AUTOSAR XML (schema 00048)
package /AUTOLIV/SoftwareComponents/SFR
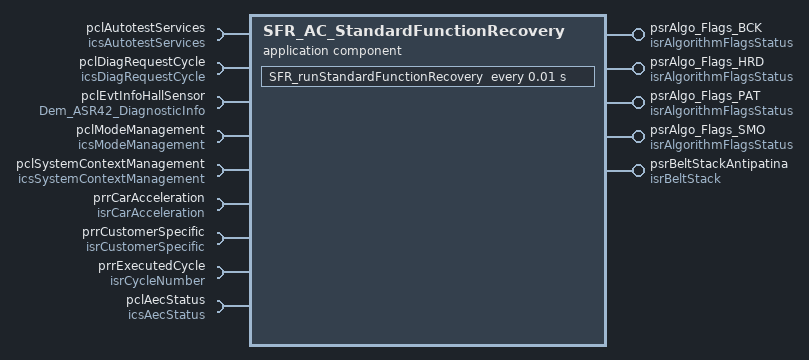
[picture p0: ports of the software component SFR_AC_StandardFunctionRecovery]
  application sw component type SFR_AC_StandardFunctionRecovery
    8 x require port:
      pclAutotestServices: required-com-specs=[GetLastCriticalAutotestID, GetTestResult], required-interface=icsAutotestServices
      pclDiagRequestCycle: required-com-specs=[ClearDiagRequestCycle, GetDiagRequestCycle], required-interface=icsDiagRequestCycle
      pclEvtInfoHallSensor: required-interface=Dem_ASR42_DiagnosticInfo
        required-com-specs:
          GetDTCOfEvent
          GetDebouncingOfEvent
          GetEventExtendedDataRecord
          GetEventExtendedDataRecordEx
          GetEventFailed
          GetEventFreezeFrameData
          GetEventFreezeFrameDataEx
          GetEventStatus
          GetEventTested
          GetFaultDetectionCounter
      pclModeManagement: client-com-spec=CheckModeStatus, required-interface=icsModeManagement
      pclSystemContextManagement: required-interface=icsSystemContextManagement
        required-com-specs:
          GetBatteryHysteresisThrs
          GetLastTensionningState
          GetMonitoredCycle
          ManageSystemContextStorage
          RestoreSystemContext
          SuperviseKL30bg
      prrCarAcceleration: nonqueued-receiver-com-spec{data-element=b8IsCarAccelerationLow, init-value=constant-reference=APPLINIT_KB8_CAR_ACCEL_LOW_TRUE}, required-interface=isrCarAcceleration
      prrCustomerSpecific: required-interface=isrCustomerSpecific
        required-com-specs:
          data-element=b8HardReleaseRequest, init-value=constant-reference=APPLINIT_KB8_BOOLEAN_FALSE
          data-element=b8IsCarCrankingActive, init-value=constant-reference=APPLINIT_KB8_CAR_CRANKING_ACTIVE_TRUE
          data-element=b8IsCarCrashDetected, init-value=constant-reference=APPLINIT_KB8_CAR_CRASH_DETECTED_FALSE
          data-element=b8IsTrigOffEventAllowed
          data-element=b8PreCrashRequestEnable, init-value=constant-reference=APPLINIT_KB8_BOOLEAN_FALSE
          data-element=u8BeltSlackStatus, init-value=constant-reference=APPLINIT_KU8_BELT_SLACK_STATUS_NOT_DEFINED
          data-element=u8HapticRequest, init-value=constant-reference=APPLINIT_KU8_HAPTIC_REQUEST_NO
          data-element=u8PreCrashRequest, init-value=constant-reference=APPLINIT_KU8_PRE_CRASH_REQUEST_NO_REQUEST
          data-element=u8TriggerRequest
          data-element=b8SignalRelInhibition
      prrExecutedCycle: nonqueued-receiver-com-spec{data-element=u8CycleNumber, init-value=constant-reference=APPLINIT_KU8_CYCLE_NUMBER_NONE}, required-interface=isrCycleNumber
    5 x provide port:
      psrAlgo_Flags_BCK: provided-interface=isrAlgorithmFlagsStatus
        provided-com-specs:
          data-element=b8InterruptFlag, uses-end-to-end-protection=true, init-value=KB8_ALGO_FLAG_OFF
          data-element=b8PreActivationFlag, uses-end-to-end-protection=true
          data-element=b8PreConditionsFlag, uses-end-to-end-protection=true
          data-element=b8TriggerFlag, uses-end-to-end-protection=true
          data-element=u8TriggeringSource, uses-end-to-end-protection=true
      psrAlgo_Flags_HRD: provided-interface=isrAlgorithmFlagsStatus
        provided-com-specs:
          data-element=b8InterruptFlag, uses-end-to-end-protection=true, init-value=constant-reference=APPLINIT_KB8_ALGO_FLAG_FALSE
          data-element=b8PreActivationFlag, uses-end-to-end-protection=true, init-value=constant-reference=APPLINIT_KB8_ALGO_FLAG_FALSE
          data-element=b8PreConditionsFlag, uses-end-to-end-protection=true, init-value=constant-reference=APPLINIT_KB8_ALGO_FLAG_FALSE
          data-element=b8TriggerFlag, uses-end-to-end-protection=true, init-value=constant-reference=APPLINIT_KB8_ALGO_FLAG_FALSE
          data-element=u8TriggeringSource, uses-end-to-end-protection=true, init-value=constant-reference=APPLINIT_KU8_TRIGGERING_SOURCE_NO
      psrAlgo_Flags_PAT: provided-interface=isrAlgorithmFlagsStatus
        provided-com-specs:
          data-element=b8InterruptFlag, uses-end-to-end-protection=true, init-value=constant-reference=APPLINIT_KB8_ALGO_FLAG_FALSE
          data-element=b8PreActivationFlag, uses-end-to-end-protection=true, init-value=constant-reference=APPLINIT_KB8_ALGO_FLAG_FALSE
          data-element=b8PreConditionsFlag, uses-end-to-end-protection=true, init-value=constant-reference=APPLINIT_KB8_ALGO_FLAG_FALSE
          data-element=b8TriggerFlag, uses-end-to-end-protection=true, init-value=constant-reference=APPLINIT_KB8_ALGO_FLAG_FALSE
          data-element=u8TriggeringSource, uses-end-to-end-protection=true, init-value=constant-reference=APPLINIT_KU8_TRIGGERING_SOURCE_NO
      psrAlgo_Flags_SMO: provided-interface=isrAlgorithmFlagsStatus
        provided-com-specs:
          data-element=b8InterruptFlag, uses-end-to-end-protection=true, init-value=constant-reference=APPLINIT_KB8_ALGO_FLAG_FALSE
          data-element=b8PreActivationFlag, uses-end-to-end-protection=true, init-value=constant-reference=APPLINIT_KB8_ALGO_FLAG_FALSE
          data-element=b8PreConditionsFlag, uses-end-to-end-protection=true, init-value=constant-reference=APPLINIT_KB8_ALGO_FLAG_FALSE
          data-element=b8TriggerFlag, uses-end-to-end-protection=true, init-value=constant-reference=APPLINIT_KB8_ALGO_FLAG_FALSE
          data-element=u8TriggeringSource, uses-end-to-end-protection=true, init-value=constant-reference=APPLINIT_KU8_TRIGGERING_SOURCE_NO
      psrBeltStackAntipatina: nonqueued-sender-com-spec=b8BeltStack, provided-interface=isrBeltStack
    require port pclAecStatus: required-interface=icsAecStatus
      required-com-specs:
        SetAecEvent
        GetNumberOfImplementedAec
        GetAecStatus
        GetAecQualificationCount
        GetAecNvpBlockRecordingStatus
        GetAecGroupsStatus
        GetAecDeskillThrs
    behavior SFR_IB_StandardFunctionRecovery: data-type-mapping=DataTypeMappingSet_PP4G
      timing event SFR_evReleasingAlgorithm: start-on-event=SFR_runStandardFunctionRecovery, period=0.01
      runnable SFR_runStandardFunctionRecovery
        data-receive-point-by-arguments:
          4 x access:
            DRP_prrCarAcceleration_b8IsCarAccelerationLow: accessed-variable=prrCarAcceleration.b8IsCarAccelerationLow
            DRP_prrCustomerSpecific_b8IsCarCrashDetected: accessed-variable=prrCustomerSpecific.b8IsCarCrashDetected
            DRP_prrExecutedCycle_u8CycleNumber: accessed-variable=prrExecutedCycle.u8CycleNumber
            drparg_b8HardReleaseRequest: accessed-variable=prrCustomerSpecific.b8HardReleaseRequest
        data-send-points:
          21 x access:
            DSP_psrAlgo_Flags_BCK_b8InterruptFlag: accessed-variable=psrAlgo_Flags_BCK.b8InterruptFlag
            DSP_psrAlgo_Flags_BCK_b8PreActivationFlag: accessed-variable=psrAlgo_Flags_BCK.b8PreActivationFlag
            DSP_psrAlgo_Flags_BCK_b8PreConditionsFlag: accessed-variable=psrAlgo_Flags_BCK.b8PreConditionsFlag
            DSP_psrAlgo_Flags_BCK_b8TriggerFlag: accessed-variable=psrAlgo_Flags_BCK.b8TriggerFlag
            DSP_psrAlgo_Flags_BCK_u8TriggeringSource: accessed-variable=psrAlgo_Flags_BCK.u8TriggeringSource
            DSP_psrAlgo_Flags_HRD_b8InterruptFlag: accessed-variable=psrAlgo_Flags_HRD.b8InterruptFlag
            DSP_psrAlgo_Flags_HRD_b8PreActivationFlag: accessed-variable=psrAlgo_Flags_HRD.b8PreActivationFlag
            DSP_psrAlgo_Flags_HRD_b8PreConditionsFlag: accessed-variable=psrAlgo_Flags_HRD.b8PreConditionsFlag
            DSP_psrAlgo_Flags_HRD_b8TriggerFlag: accessed-variable=psrAlgo_Flags_HRD.b8TriggerFlag
            DSP_psrAlgo_Flags_HRD_u8TriggeringSource: accessed-variable=psrAlgo_Flags_HRD.u8TriggeringSource
            DSP_psrAlgo_Flags_PAT_b8InterruptFlag: accessed-variable=psrAlgo_Flags_PAT.b8InterruptFlag
            DSP_psrAlgo_Flags_PAT_b8PreActivationFlag: accessed-variable=psrAlgo_Flags_PAT.b8PreActivationFlag
            DSP_psrAlgo_Flags_PAT_b8PreConditionsFlag: accessed-variable=psrAlgo_Flags_PAT.b8PreConditionsFlag
            DSP_psrAlgo_Flags_PAT_b8TriggerFlag: accessed-variable=psrAlgo_Flags_PAT.b8TriggerFlag
            DSP_psrAlgo_Flags_PAT_u8TriggeringSource: accessed-variable=psrAlgo_Flags_PAT.u8TriggeringSource
            DSP_psrAlgo_Flags_SMO_b8InterruptFlag: accessed-variable=psrAlgo_Flags_SMO.b8InterruptFlag
            DSP_psrAlgo_Flags_SMO_b8PreActivationFlag: accessed-variable=psrAlgo_Flags_SMO.b8PreActivationFlag
            DSP_psrAlgo_Flags_SMO_b8PreConditionsFlag: accessed-variable=psrAlgo_Flags_SMO.b8PreConditionsFlag
            DSP_psrAlgo_Flags_SMO_b8TriggerFlag: accessed-variable=psrAlgo_Flags_SMO.b8TriggerFlag
            DSP_psrAlgo_Flags_SMO_u8TriggeringSource: accessed-variable=psrAlgo_Flags_SMO.u8TriggeringSource
            dsp_b8BeltStack: accessed-variable=psrBeltStackAntipatina.b8BeltStack
        7 x sync call:
          SSCP_pclDiagRequestCycle_ClearDiagRequestCycle: operation=pclDiagRequestCycle.ClearDiagRequestCycle
          SSCP_pclDiagRequestCycle_GetDiagRequestCycle: operation=pclDiagRequestCycle.GetDiagRequestCycle
          SSCP_pclModeManagement_CheckModeStatus: operation=pclModeManagement.CheckModeStatus
          SSCP_pclSystemContextManagement_GetLastTensionningState: operation=pclSystemContextManagement.GetLastTensionningState
          SSCP_pclTestResult_GetTestResult: operation=pclAutotestServices.GetTestResult
          scp_GetEventStatus: operation=pclEvtInfoHallSensor.GetEventStatus
          SC_pclAecStatus_GetAecStatus: operation=pclAecStatus.GetAecStatus
  swc implementation SFR_AC_StandardFunctionRecovery_Implementation: behavior=SFR_IB_StandardFunctionRecovery
